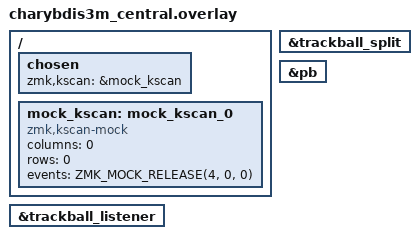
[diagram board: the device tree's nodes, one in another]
#include <dt-bindings/zmk/kscan_mock.h>
#include "charybdis3m.dtsi"

/* The dongle has no keys: keep the matrix transform from charybdis3m.dtsi
 * (it sets the keymap length) but scan nothing locally. */
/delete-node/ &kscan0;

&trackball_split {
    status = "okay";
};

&trackball_listener {
    status = "okay";
};

&pb {
    status = "okay";
};

/ {
    chosen {
        zmk,kscan = &mock_kscan;
    };

    mock_kscan: mock_kscan_0 {
        compatible = "zmk,kscan-mock";

        columns = <0>;
        rows = <0>;
        /* kscan-mock needs at least one event; RC(4,0) is not in the
         * matrix transform, so it is dropped instead of sending a key. */
        events = <ZMK_MOCK_RELEASE(4, 0, 0)>;
    };
};
